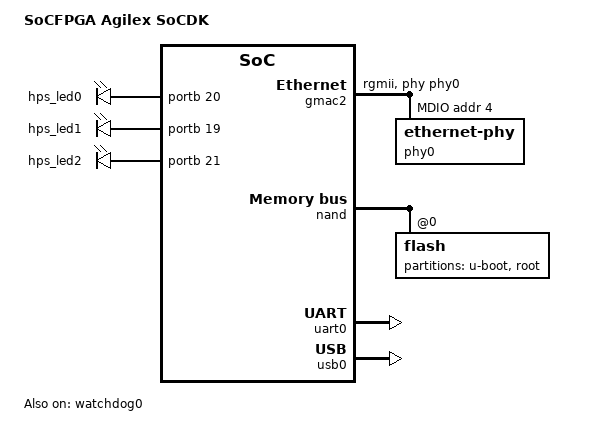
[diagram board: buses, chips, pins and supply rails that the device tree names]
#include "socfpga_agilex.dtsi"
/ {
	model = "SoCFPGA Agilex SoCDK";
	compatible = "intel,socfpga-agilex-socdk", "intel,socfpga-agilex";
	aliases {
		serial0 = &uart0;
		ethernet0 = &gmac0;
		ethernet1 = &gmac1;
		ethernet2 = &gmac2;
	};
	chosen {
		stdout-path = "serial0:115200n8";
	};
	leds {
		compatible = "gpio-leds";
		led0 {
			label = "hps_led0";
			gpios = <&portb 20 GPIO_ACTIVE_HIGH>;
		};
		led1 {
			label = "hps_led1";
			gpios = <&portb 19 GPIO_ACTIVE_HIGH>;
		};
		led2 {
			label = "hps_led2";
			gpios = <&portb 21 GPIO_ACTIVE_HIGH>;
		};
	};
	memory@80000000 {
		device_type = "memory";
		reg = <0 0x80000000 0 0>;
	};
};
&gpio1 {
	status = "okay";
};
&gmac2 {
	status = "okay";
	phy-mode = "rgmii";
	phy-handle = <&phy0>;
	max-frame-size = <9000>;
	mdio0 {
		#address-cells = <1>;
		#size-cells = <0>;
		compatible = "snps,dwmac-mdio";
		phy0: ethernet-phy@0 {
			reg = <4>;
			txd0-skew-ps = <0>;  
			txd1-skew-ps = <0>;  
			txd2-skew-ps = <0>;  
			txd3-skew-ps = <0>;  
			rxd0-skew-ps = <420>;  
			rxd1-skew-ps = <420>;  
			rxd2-skew-ps = <420>;  
			rxd3-skew-ps = <420>;  
			txen-skew-ps = <0>;  
			txc-skew-ps = <900>;  
			rxdv-skew-ps = <420>;  
			rxc-skew-ps = <1680>;  
		};
	};
};
&nand {
	status = "okay";
	flash@0 {
		#address-cells = <1>;
		#size-cells = <1>;
		reg = <0>;
		nand-bus-width = <16>;
		partition@0 {
			label = "u-boot";
			reg = <0 0x200000>;
		};
		partition@200000 {
			label = "root";
			reg = <0x200000 0x3fe00000>;
		};
	};
};
&osc1 {
	clock-frequency = <25000000>;
};
&uart0 {
	status = "okay";
};
&usb0 {
	status = "okay";
	disable-over-current;
};
&watchdog0 {
	status = "okay";
};
